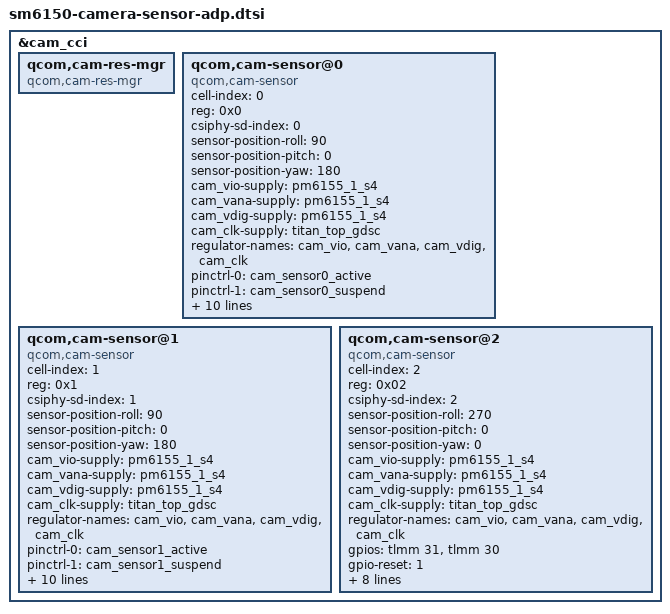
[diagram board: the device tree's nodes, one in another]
/*
 * Copyright (c) 2018-2019, The Linux Foundation. All rights reserved.
 *
 * This program is free software; you can redistribute it and/or modify
 * it under the terms of the GNU General Public License version 2 and
 * only version 2 as published by the Free Software Foundation.
 *
 * This program is distributed in the hope that it will be useful,
 * but WITHOUT ANY WARRANTY; without even the implied warranty of
 * MERCHANTABILITY or FITNESS FOR A PARTICULAR PURPOSE.  See the
 * GNU General Public License for more details.
 */

&cam_cci {
	qcom,cam-res-mgr {
		compatible = "qcom,cam-res-mgr";
		status = "ok";
	};

	qcom,cam-sensor@0 {
		cell-index = <0>;
		compatible = "qcom,cam-sensor";
		reg = <0x0>;
		csiphy-sd-index = <0>;
		sensor-position-roll = <90>;
		sensor-position-pitch = <0>;
		sensor-position-yaw = <180>;


		cam_vio-supply = <&pm6155_1_s4>;
		cam_vana-supply = <&pm6155_1_s4>;
		cam_vdig-supply = <&pm6155_1_s4>;
		cam_clk-supply = <&titan_top_gdsc>;
		regulator-names = "cam_vio", "cam_vana", "cam_vdig",
			"cam_clk";
		pinctrl-names = "sensor_default", "sensor_suspend";
		pinctrl-0 = <&cam_sensor0_active>;
		pinctrl-1 = <&cam_sensor0_suspend>;
		gpios = <&tlmm 28 0>;
		gpio-reset = <0>;
		gpio-req-tbl-num = <0>;
		gpio-req-tbl-flags = <0>;
		gpio-req-tbl-label = "CAM_RESET0";
		sensor-mode = <0>;
		cci-master = <0>;
		status = "ok";
		clocks = <&clock_camcc CAM_CC_MCLK0_CLK>;
		clock-names = "cam_clk";
		clock-cntl-level = "turbo";
		clock-rates = <24000000>;
	};

	qcom,cam-sensor@1 {
		cell-index = <1>;
		compatible = "qcom,cam-sensor";
		reg = <0x1>;
		csiphy-sd-index = <1>;
		sensor-position-roll = <90>;
		sensor-position-pitch = <0>;
		sensor-position-yaw = <180>;

		cam_vio-supply = <&pm6155_1_s4>;
		cam_vana-supply = <&pm6155_1_s4>;
		cam_vdig-supply = <&pm6155_1_s4>;
		cam_clk-supply = <&titan_top_gdsc>;
		regulator-names = "cam_vio", "cam_vana", "cam_vdig",
			"cam_clk";
		pinctrl-names = "sensor_default", "sensor_suspend";
		pinctrl-0 = <&cam_sensor1_active>;
		pinctrl-1 = <&cam_sensor1_suspend>;
		gpios = <&tlmm 29 0>;
		gpio-reset = <0>;
		gpio-req-tbl-num = <0>;
		gpio-req-tbl-flags = <0>;
		gpio-req-tbl-label = "CAM_RESET1";
		sensor-mode = <0>;
		cci-master = <0>;
		status = "ok";
		clocks = <&clock_camcc CAM_CC_MCLK1_CLK>;
		clock-names = "cam_clk";
		clock-cntl-level = "turbo";
		clock-rates = <24000000>;
	};

	qcom,cam-sensor@2 {
		cell-index = <2>;
		compatible = "qcom,cam-sensor";
		reg = <0x02>;
		csiphy-sd-index = <2>;
		sensor-position-roll = <270>;
		sensor-position-pitch = <0>;
		sensor-position-yaw = <0>;

		cam_vio-supply = <&pm6155_1_s4>;
		cam_vana-supply = <&pm6155_1_s4>;
		cam_vdig-supply = <&pm6155_1_s4>;
		cam_clk-supply = <&titan_top_gdsc>;
		regulator-names = "cam_vio", "cam_vana", "cam_vdig",
			"cam_clk";
		gpios = <&tlmm 31 0>,
			<&tlmm 30 0>;
		gpio-reset = <1>;
		gpio-req-tbl-num = <0 1>;
		gpio-req-tbl-flags = <1 0>;
		gpio-req-tbl-label = "CAMIF_MCLK2",
					"CAM_RESET2";
		sensor-mode = <0>;
		cci-master = <1>;
		status = "ok";
		clocks = <&clock_camcc CAM_CC_MCLK2_CLK>;
		clock-names = "cam_clk";
		clock-cntl-level = "turbo";
		clock-rates = <24000000>;
	};
};
